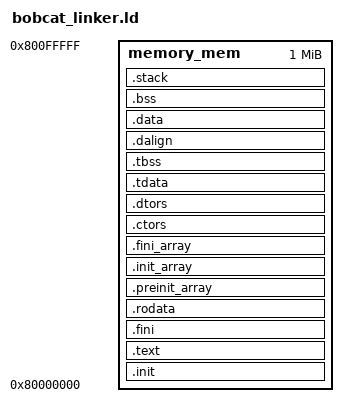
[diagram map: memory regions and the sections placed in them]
ENTRY(_start)
MEMORY
{
    memory_mem : ORIGIN = 0x80000000, LENGTH = 0x100000
}

SECTIONS
{
  __stack_size = DEFINED(__stack_size) ? __stack_size : 1M;

  .init           :
  {
    KEEP (*(SORT_NONE(.init)))
  } >memory_mem

  .text           :
  {
    *(.text .text.*)
  } >memory_mem

  .fini           :
  {
    KEEP (*(SORT_NONE(.fini)))
  } >memory_mem

  PROVIDE (__etext = .);
  PROVIDE (_etext = .);
  PROVIDE (etext = .);

  .rodata         :
  {
    *(.rdata)
    *(.rodata .rodata.*)
    *(.gnu.linkonce.r.*)
  } >memory_mem

  . = ALIGN(4);

  .preinit_array  :
  {
    PROVIDE_HIDDEN (__preinit_array_start = .);
    KEEP (*(.preinit_array))
    PROVIDE_HIDDEN (__preinit_array_end = .);
  } >memory_mem

  .init_array     :
  {
    PROVIDE_HIDDEN (__init_array_start = .);
    KEEP (*(SORT_BY_INIT_PRIORITY(.init_array.*) SORT_BY_INIT_PRIORITY(.ctors.*)))
    KEEP (*(.init_array EXCLUDE_FILE (*crtbegin.o *crtbegin?.o *crtend.o *crtend?.o ) .ctors))
    PROVIDE_HIDDEN (__init_array_end = .);
  } >memory_mem

  .fini_array     :
  {
    PROVIDE_HIDDEN (__fini_array_start = .);
    KEEP (*(SORT_BY_INIT_PRIORITY(.fini_array.*) SORT_BY_INIT_PRIORITY(.dtors.*)))
    KEEP (*(.fini_array EXCLUDE_FILE (*crtbegin.o *crtbegin?.o *crtend.o *crtend?.o ) .dtors))
    PROVIDE_HIDDEN (__fini_array_end = .);
  } >memory_mem

  .ctors          :
  {
    /* gcc uses crtbegin.o to find the start of
       the constructors, so we make sure it is
       first.  Because this is a wildcard, it
       doesn't matter if the user does not
       actually link against crtbegin.o; the
       linker won't look for a file to match a
       wildcard.  The wildcard also means that it
       doesn't matter which directory crtbegin.o
       is in.  */
    KEEP (*crtbegin.o(.ctors))
    KEEP (*crtbegin?.o(.ctors))
    /* We don't want to include the .ctor section from
       the crtend.o file until after the sorted ctors.
       The .ctor section from the crtend file contains the
       end of ctors marker and it must be last */
    KEEP (*(EXCLUDE_FILE (*crtend.o *crtend?.o ) .ctors))
    KEEP (*(SORT(.ctors.*)))
    KEEP (*(.ctors))
  } >memory_mem

  .dtors          :
  {
    KEEP (*crtbegin.o(.dtors))
    KEEP (*crtbegin?.o(.dtors))
    KEEP (*(EXCLUDE_FILE (*crtend.o *crtend?.o ) .dtors))
    KEEP (*(SORT(.dtors.*)))
    KEEP (*(.dtors))
  } >memory_mem
  
  .tdata :
  {
    PROVIDE( _tdata_begin = . );
    *(.tdata)
    PROVIDE( _tdata_end = . );
  } >memory_mem
  .tbss :
  {
    *(.tbss)
    PROVIDE( _tbss_end = . );
  } >memory_mem

  .dalign         :
  {
    . = ALIGN(4);
    PROVIDE( _data = . );
  } >memory_mem

  .data          :
  {
    *(.data .data.*)
    *(.gnu.linkonce.d.*)
    . = ALIGN(8);
    PROVIDE( __global_pointer$ = . + 0x800 );
    *(.sdata .sdata.*)
    *(.gnu.linkonce.s.*)
    . = ALIGN(8);
    *(.srodata.cst16)
    *(.srodata.cst8)
    *(.srodata.cst4)
    *(.srodata.cst2)
    *(.srodata .srodata.*)
  } >memory_mem

  . = ALIGN(4);
  PROVIDE( _edata = . );
  PROVIDE( edata = . );

  PROVIDE( _fbss = . );
  PROVIDE( __bss_start = . );
  .bss            :
  {
    *(.sbss*)
    *(.gnu.linkonce.sb.*)
    *(.bss .bss.*)
    *(.gnu.linkonce.b.*)
    *(COMMON)
    . = ALIGN(4);
  } >memory_mem

  . = ALIGN(8);
  PROVIDE( _ebss = . );
  PROVIDE( _end = . );
  PROVIDE( end = . );

  .stack ORIGIN(memory_mem) + LENGTH(memory_mem) - __stack_size :
  {
    PROVIDE( _heap_end = . );
    . = __stack_size;
    PROVIDE( _sp = . );
  } >memory_mem
}
